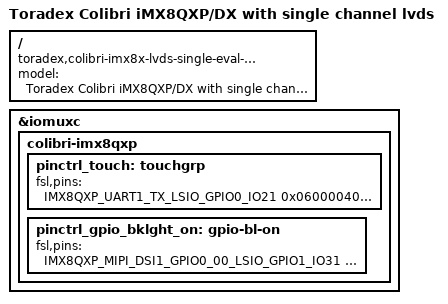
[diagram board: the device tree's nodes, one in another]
// SPDX-License-Identifier: GPL-2.0+ OR X11
/*
 * Copyright 2018-2019 Toradex
 */

/dts-v1/;

#include "dt-bindings/pwm/pwm.h"
#include "imx8qxp-colibri.dtsi"
#include "imx8qxp-colibri-eval-v3.dtsi"

/ {
	model = "Toradex Colibri iMX8QXP/DX with single channel lvds";
	compatible = "toradex,colibri-imx8x-lvds-single-eval-v3",
		     "toradex,colibri-imx8x",
		     "fsl,imx8qxp";
};

&iomuxc {
	pinctrl-names = "default";

	colibri-imx8qxp {
		pinctrl_touch: touchgrp {
			fsl,pins = <
				IMX8QXP_UART1_TX_LSIO_GPIO0_IO21		0x06000040	/* SODIMM  28 */
				IMX8QXP_UART1_RX_LSIO_GPIO0_IO22		0x06000020	/* SODIMM  30 */
			>;
		};

		pinctrl_gpio_bklght_on: gpio-bl-on {
			fsl,pins = <
				IMX8QXP_MIPI_DSI1_GPIO0_00_LSIO_GPIO1_IO31	0x00000020
			>;
		};
	};
};
